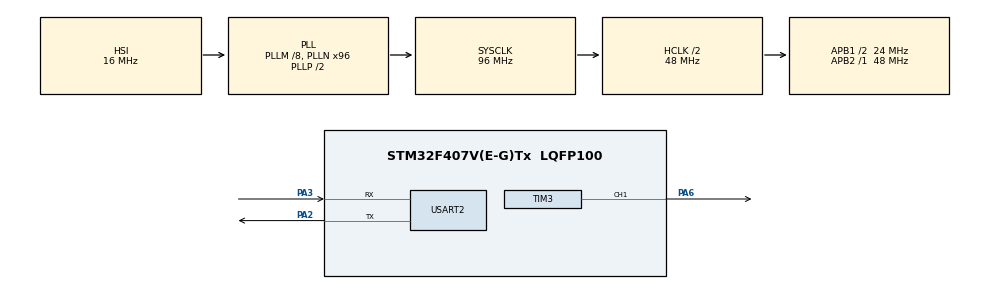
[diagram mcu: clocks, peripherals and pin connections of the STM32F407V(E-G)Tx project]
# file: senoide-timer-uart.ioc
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Dma.Request0=TIM3_CH1/TRIG
Dma.TIM3_CH1/TRIG.0.Direction=DMA_MEMORY_TO_PERIPH
Dma.TIM3_CH1/TRIG.0.FIFOMode=DMA_FIFOMODE_DISABLE
Dma.TIM3_CH1/TRIG.0.Instance=DMA1_Stream4
Dma.TIM3_CH1/TRIG.0.MemDataAlignment=DMA_MDATAALIGN_HALFWORD
Dma.TIM3_CH1/TRIG.0.MemInc=DMA_MINC_ENABLE
Dma.TIM3_CH1/TRIG.0.Mode=DMA_CIRCULAR
Dma.TIM3_CH1/TRIG.0.PeriphDataAlignment=DMA_PDATAALIGN_HALFWORD
Dma.TIM3_CH1/TRIG.0.PeriphInc=DMA_PINC_DISABLE
Dma.TIM3_CH1/TRIG.0.Priority=DMA_PRIORITY_LOW
Mcu.Family=STM32F4
Mcu.Name=STM32F407V(E-G)Tx
Mcu.Package=LQFP100
NVIC.DMA1_Stream4_IRQn=true\:0\:0\:false\:false\:true\:false\:true\:true
NVIC.PriorityGroup=NVIC_PRIORITYGROUP_4
NVIC.USART2_IRQn=true\:0\:0\:false\:false\:true\:true\:true\:true
PA2.Mode=Asynchronous
PA2.Signal=USART2_TX
PA3.Mode=Asynchronous
PA3.Signal=USART2_RX
PA6.Signal=S_TIM3_CH1
ProjectManager.HeapSize=0x200
ProjectManager.StackSize=0x400
ProjectManager.TargetToolchain=STM32CubeIDE
RCC.48MHZClocksFreq_Value=48000000
RCC.AHBCLKDivider=RCC_SYSCLK_DIV2
RCC.AHBFreq_Value=48000000
RCC.APB1CLKDivider=RCC_HCLK_DIV2
RCC.APB1Freq_Value=24000000
RCC.APB1TimFreq_Value=48000000
RCC.APB2Freq_Value=48000000
RCC.APB2TimFreq_Value=48000000
RCC.CortexFreq_Value=48000000
RCC.HCLKFreq_Value=48000000
RCC.HSE_VALUE=25000000
RCC.HSI_VALUE=16000000
RCC.LSE_VALUE=32768
RCC.PLLM=8
RCC.PLLN=96
RCC.SYSCLKFreq_VALUE=96000000
RCC.SYSCLKSource=RCC_SYSCLKSOURCE_PLLCLK
RCC.VCOOutputFreq_Value=192000000
SH.S_TIM3_CH1.0=TIM3_CH1,PWM Generation1 CH1
TIM3.Channel-PWM\ Generation1\ CH1=TIM_CHANNEL_1
TIM3.Period=199
TIM3.Prescaler=23
TIM3.Pulse-PWM\ Generation1\ CH1=50
USART2.VirtualMode=VM_ASYNC
board=custom

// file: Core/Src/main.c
/* USER CODE BEGIN Header */
/**
  ******************************************************************************
  * @file           : main.c
  * @brief          : Main program body
  ******************************************************************************
  * @attention
  *
  * Copyright (c) 2026 STMicroelectronics.
  * All rights reserved.
  *
  * This software is licensed under terms that can be found in the LICENSE file
  * in the root directory of this software component.
  * If no LICENSE file comes with this software, it is provided AS-IS.
  *
  ******************************************************************************
  */
/* USER CODE END Header */
#include "main.h"
#include "math.h"
#include <stdlib.h>

char rx_buffer[10];
float freq = 50;

/* USER CODE BEGIN PD */
#define PI 3.14159
#define ASR 1.8
/* USER CODE END PD */

TIM_HandleTypeDef htim3;
DMA_HandleTypeDef hdma_tim3_ch1_trig;

UART_HandleTypeDef huart2;

void SystemClock_Config(void);
static void MX_GPIO_Init(void);
static void MX_DMA_Init(void);
static void MX_TIM3_Init(void);
static void MX_USART2_UART_Init(void);

int main(void)
{

  /* USER CODE BEGIN 1 */
  uint16_t IV[200];
  float angle = 0;
  /* USER CODE END 1 */

  /* MCU Configuration--------------------------------------------------------*/

  /* Reset of all peripherals, Initializes the Flash interface and the Systick. */
  HAL_Init();

  /* Configure the system clock */
  SystemClock_Config();

  /* Initialize all configured peripherals */
  MX_GPIO_Init();
  MX_DMA_Init();
  MX_TIM3_Init();
  MX_USART2_UART_Init();
  /* USER CODE BEGIN 2 */

  for (int i = 0; i < 200; i++) {
      angle = (float) i * ASR;
      IV[i] = (uint16_t) rint(100 + 99*sinf(angle*(PI/180)));
  }
  /* USER CODE END 2 */
  HAL_TIM_PWM_Start_DMA(&htim3, TIM_CHANNEL_1, (uint32_t*)IV, 200);
  HAL_UART_Receive_IT(&huart2, (uint8_t*)rx_buffer, sizeof(rx_buffer));
  /* Infinite loop */
  while (1)
  {

  }
}

void SystemClock_Config(void)
{
  RCC_OscInitTypeDef RCC_OscInitStruct = {0};
  RCC_ClkInitTypeDef RCC_ClkInitStruct = {0};

  /** Configure the main internal regulator output voltage
  */
  __HAL_RCC_PWR_CLK_ENABLE();
  __HAL_PWR_VOLTAGESCALING_CONFIG(PWR_REGULATOR_VOLTAGE_SCALE1);

  /** Initializes the RCC Oscillators according to the specified parameters
  * in the RCC_OscInitTypeDef structure.
  */
  RCC_OscInitStruct.OscillatorType = RCC_OSCILLATORTYPE_HSI;
  RCC_OscInitStruct.HSIState = RCC_HSI_ON;
  RCC_OscInitStruct.HSICalibrationValue = RCC_HSICALIBRATION_DEFAULT;
  RCC_OscInitStruct.PLL.PLLState = RCC_PLL_ON;
  RCC_OscInitStruct.PLL.PLLSource = RCC_PLLSOURCE_HSI;
  RCC_OscInitStruct.PLL.PLLM = 8;
  RCC_OscInitStruct.PLL.PLLN = 96;
  RCC_OscInitStruct.PLL.PLLP = RCC_PLLP_DIV2;
  RCC_OscInitStruct.PLL.PLLQ = 4;
  if (HAL_RCC_OscConfig(&RCC_OscInitStruct) != HAL_OK)
  {
    Error_Handler();
  }

  /** Initializes the CPU, AHB and APB buses clocks
  */
  RCC_ClkInitStruct.ClockType = RCC_CLOCKTYPE_HCLK|RCC_CLOCKTYPE_SYSCLK
                              |RCC_CLOCKTYPE_PCLK1|RCC_CLOCKTYPE_PCLK2;
  RCC_ClkInitStruct.SYSCLKSource = RCC_SYSCLKSOURCE_PLLCLK;
  RCC_ClkInitStruct.AHBCLKDivider = RCC_SYSCLK_DIV2;
  RCC_ClkInitStruct.APB1CLKDivider = RCC_HCLK_DIV2;
  RCC_ClkInitStruct.APB2CLKDivider = RCC_HCLK_DIV1;

  if (HAL_RCC_ClockConfig(&RCC_ClkInitStruct, FLASH_LATENCY_1) != HAL_OK)
  {
    Error_Handler();
  }
}

static void MX_TIM3_Init(void)
{

  TIM_MasterConfigTypeDef sMasterConfig = {0};
  TIM_OC_InitTypeDef sConfigOC = {0};

  htim3.Instance = TIM3;
  htim3.Init.Prescaler = 23;
  htim3.Init.CounterMode = TIM_COUNTERMODE_UP;
  htim3.Init.Period = 199;
  htim3.Init.ClockDivision = TIM_CLOCKDIVISION_DIV1;
  htim3.Init.AutoReloadPreload = TIM_AUTORELOAD_PRELOAD_DISABLE;
  if (HAL_TIM_PWM_Init(&htim3) != HAL_OK)
  {
    Error_Handler();
  }
  sMasterConfig.MasterOutputTrigger = TIM_TRGO_RESET;
  sMasterConfig.MasterSlaveMode = TIM_MASTERSLAVEMODE_DISABLE;
  if (HAL_TIMEx_MasterConfigSynchronization(&htim3, &sMasterConfig) != HAL_OK)
  {
    Error_Handler();
  }
  sConfigOC.OCMode = TIM_OCMODE_PWM1;
  sConfigOC.Pulse = 50;
  sConfigOC.OCPolarity = TIM_OCPOLARITY_HIGH;
  sConfigOC.OCFastMode = TIM_OCFAST_DISABLE;
  if (HAL_TIM_PWM_ConfigChannel(&htim3, &sConfigOC, TIM_CHANNEL_1) != HAL_OK)
  {
    Error_Handler();
  }
  HAL_TIM_MspPostInit(&htim3);

}

static void MX_USART2_UART_Init(void)
{

  huart2.Instance = USART2;
  huart2.Init.BaudRate = 115200;
  huart2.Init.WordLength = UART_WORDLENGTH_8B;
  huart2.Init.StopBits = UART_STOPBITS_1;
  huart2.Init.Parity = UART_PARITY_NONE;
  huart2.Init.Mode = UART_MODE_TX_RX;
  huart2.Init.HwFlowCtl = UART_HWCONTROL_NONE;
  huart2.Init.OverSampling = UART_OVERSAMPLING_16;
  if (HAL_UART_Init(&huart2) != HAL_OK)
  {
    Error_Handler();
  }

}

static void MX_DMA_Init(void)
{

  /* DMA controller clock enable */
  __HAL_RCC_DMA1_CLK_ENABLE();

  /* DMA interrupt init */
  /* DMA1_Stream4_IRQn interrupt configuration */
  HAL_NVIC_SetPriority(DMA1_Stream4_IRQn, 0, 0);
  HAL_NVIC_EnableIRQ(DMA1_Stream4_IRQn);

}

static void MX_GPIO_Init(void)
{

  /* GPIO Ports Clock Enable */
  __HAL_RCC_GPIOA_CLK_ENABLE(	);

}

/* USER CODE BEGIN 4 */
void HAL_UART_RxCpltCallback(UART_HandleTypeDef *huart)
{
    if (huart->Instance == USART2)
    {
        rx_buffer[sizeof(rx_buffer)-1] = '\0';
        freq = atof(rx_buffer);

        // recalcula ARR
        uint32_t arr = (48000000 / ((23 + 1) * freq * 200)) - 1;

        __HAL_TIM_SET_AUTORELOAD(&htim3, arr);

        // reinicia recepção
        HAL_UART_Receive_IT(&huart2, (uint8_t*)rx_buffer, sizeof(rx_buffer));
    }
}
/* USER CODE END 4 */

void Error_Handler(void)
{
  __disable_irq();
  while (1)
  {
  }
}
